VERSION ""

NS_ :

BS_:

BU_: bms bms_diag vcu charger motor dash

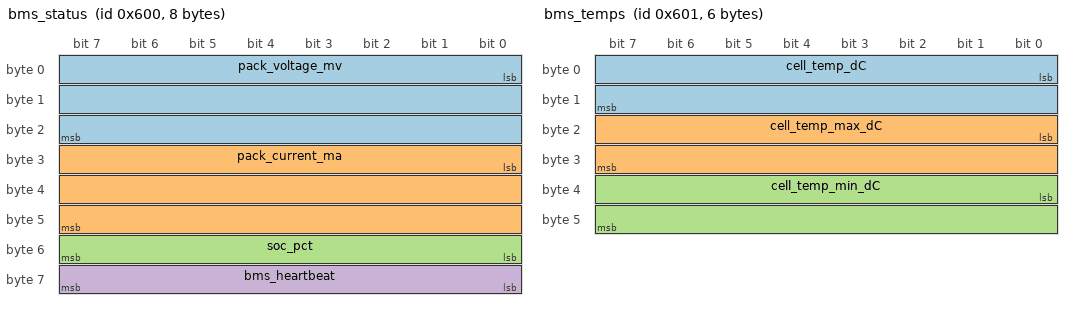
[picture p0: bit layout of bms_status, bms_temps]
BO_ 1536 bms_status: 8 bms
 SG_ pack_voltage_mv : 0|24@1+ (1,0) [0|16777215] "" Vector__XXX
 SG_ pack_current_ma : 24|24@1- (1,0) [-8388608|8388607] "" Vector__XXX
 SG_ soc_pct : 48|8@1+ (1,0) [0|255] "" Vector__XXX
 SG_ bms_heartbeat : 56|8@1+ (1,0) [0|255] "" Vector__XXX

BO_ 1537 bms_temps: 6 bms
 SG_ cell_temp_dC : 0|16@1- (1,0) [-32768|32767] "" Vector__XXX
 SG_ cell_temp_max_dC : 16|16@1- (1,0) [-32768|32767] "" Vector__XXX
 SG_ cell_temp_min_dC : 32|16@1- (1,0) [-32768|32767] "" Vector__XXX

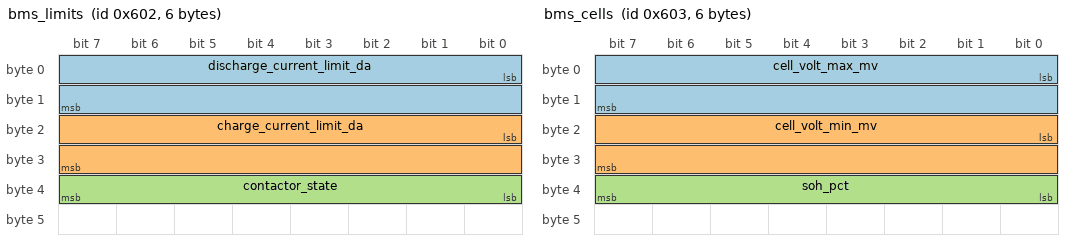
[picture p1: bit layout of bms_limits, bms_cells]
BO_ 1538 bms_limits: 6 bms
 SG_ discharge_current_limit_da : 0|16@1+ (1,0) [0|65535] "" Vector__XXX
 SG_ charge_current_limit_da : 16|16@1+ (1,0) [0|65535] "" Vector__XXX
 SG_ contactor_state : 32|8@1+ (1,0) [0|255] "" Vector__XXX

BO_ 1539 bms_cells: 6 bms
 SG_ cell_volt_max_mv : 0|16@1+ (1,0) [0|65535] "" Vector__XXX
 SG_ cell_volt_min_mv : 16|16@1+ (1,0) [0|65535] "" Vector__XXX
 SG_ soh_pct : 32|8@1+ (1,0) [0|255] "" Vector__XXX

BO_ 1540 bms_fault: 8 bms
 SG_ fault_code : 0|8@1+ (1,0) [0|255] "" Vector__XXX
 SG_ fault_counter : 8|8@1+ (1,0) [0|255] "" Vector__XXX

BO_ 1552 bms_diag_response: 8 bms_diag
 SG_ diag_response_code : 0|8@1+ (1,0) [0|255] "" Vector__XXX
 SG_ dtc_id : 16|16@1+ (1,0) [0|65535] "" Vector__XXX

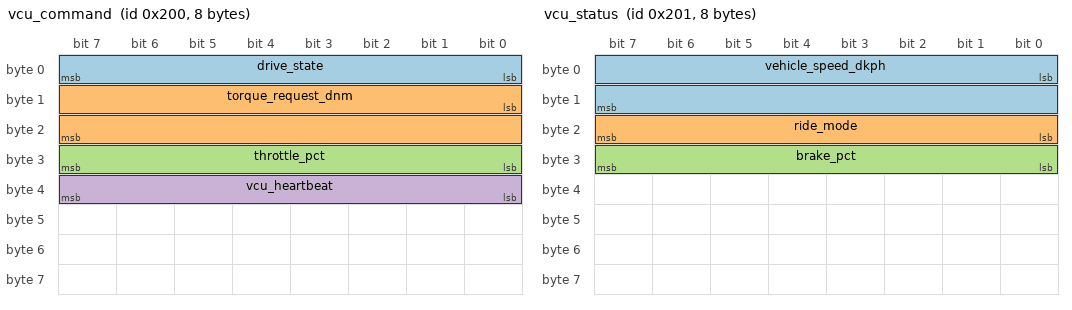
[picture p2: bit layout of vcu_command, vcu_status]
BO_ 512 vcu_command: 8 vcu
 SG_ drive_state : 0|8@1+ (1,0) [0|255] "" Vector__XXX
 SG_ torque_request_dnm : 8|16@1- (1,0) [-32768|32767] "" Vector__XXX
 SG_ throttle_pct : 24|8@1+ (1,0) [0|255] "" Vector__XXX
 SG_ vcu_heartbeat : 32|8@1+ (1,0) [0|255] "" Vector__XXX

BO_ 513 vcu_status: 8 vcu
 SG_ vehicle_speed_dkph : 0|16@1+ (1,0) [0|65535] "" Vector__XXX
 SG_ ride_mode : 16|8@1+ (1,0) [0|255] "" Vector__XXX
 SG_ brake_pct : 24|8@1+ (1,0) [0|255] "" Vector__XXX

BO_ 514 vcu_charge_control: 4 vcu
 SG_ charge_enable : 0|8@1+ (1,0) [0|255] "" Vector__XXX
 SG_ charge_current_request_da : 8|16@1+ (1,0) [0|65535] "" Vector__XXX

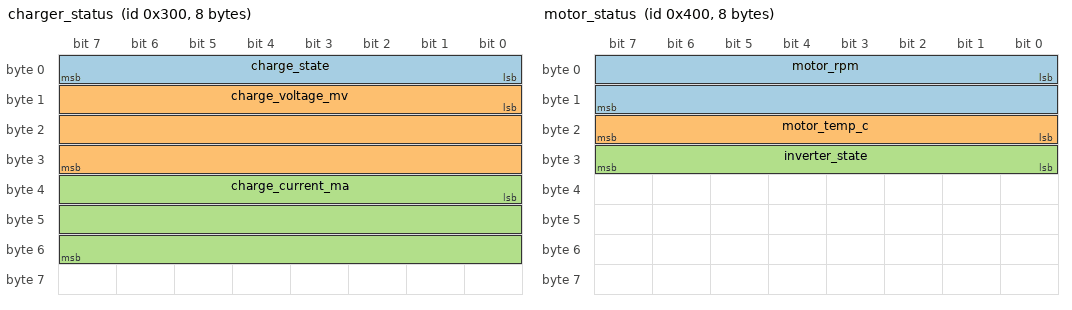
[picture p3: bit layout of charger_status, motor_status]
BO_ 768 charger_status: 8 charger
 SG_ charge_state : 0|8@1+ (1,0) [0|255] "" Vector__XXX
 SG_ charge_voltage_mv : 8|24@1+ (1,0) [0|16777215] "" Vector__XXX
 SG_ charge_current_ma : 32|24@1+ (1,0) [0|16777215] "" Vector__XXX

BO_ 769 charger_limits: 4 charger
 SG_ charge_plug_state : 0|8@1+ (1,0) [0|255] "" Vector__XXX
 SG_ max_charge_current_da : 8|16@1+ (1,0) [0|65535] "" Vector__XXX

BO_ 1024 motor_status: 8 motor
 SG_ motor_rpm : 0|16@1- (1,0) [-32768|32767] "" Vector__XXX
 SG_ motor_temp_c : 16|8@1- (1,0) [-128|127] "" Vector__XXX
 SG_ inverter_state : 24|8@1+ (1,0) [0|255] "" Vector__XXX

BO_ 1025 motor_power: 6 motor
 SG_ dc_bus_voltage_mv : 0|24@1+ (1,0) [0|16777215] "" Vector__XXX
 SG_ phase_current_ma : 24|24@1- (1,0) [-8388608|8388607] "" Vector__XXX

BO_ 1026 motor_wheel: 4 motor
 SG_ wheel_speed_rpm : 0|16@1+ (1,0) [0|65535] "" Vector__XXX
 SG_ regen_active : 16|8@1+ (1,0) [0|255] "" Vector__XXX

BO_ 1280 dash_telltales: 4 dash

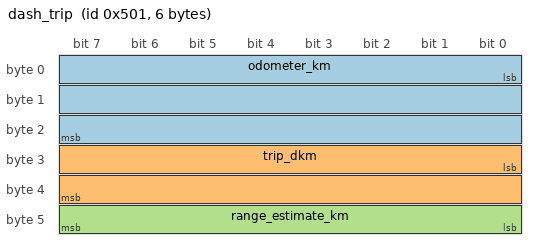
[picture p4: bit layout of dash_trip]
BO_ 1281 dash_trip: 6 dash
 SG_ odometer_km : 0|24@1+ (1,0) [0|16777215] "" Vector__XXX
 SG_ trip_dkm : 24|16@1+ (1,0) [0|65535] "" Vector__XXX
 SG_ range_estimate_km : 40|8@1+ (1,0) [0|255] "" Vector__XXX

CM_ "Generated by gen_dbc.py from catalog.yml. Do not edit by hand: edit the contract and regenerate, so this file and the test harness can never disagree. Byte-aligned subset; anything the subset cannot express is reported by the generator, never dropped silently.";

VAL_ 1540 fault_code 0 "NONE" 1 "OVERTEMP" 2 "OVERVOLT" 3 "UNDERVOLT" 4 "HEARTBEAT_LOST" 5 "CHARGE_LOST" 6 "OVERCURRENT" 7 "ISOLATION_FAULT" ;
VAL_ 1538 contactor_state 0 "OPEN" 1 "PRECHARGE" 2 "CLOSED" 3 "WELDED" 4 "FAULT" ;
VAL_ 512 drive_state 0 "PARKED" 1 "READY" 2 "DRIVE" 3 "REVERSE" 4 "LIMP" 5 "SHUTDOWN" ;
VAL_ 513 ride_mode 0 "ECO" 1 "CITY" 2 "SPORT" 3 "SERVICE" ;
VAL_ 768 charge_state 0 "IDLE" 1 "CONNECTED" 2 "HANDSHAKE" 3 "CONSTANT_CURRENT" 4 "CONSTANT_VOLTAGE" 5 "COMPLETE" 6 "SUSPENDED" 7 "FAULT" ;
VAL_ 769 charge_plug_state 0 "UNPLUGGED" 1 "PLUGGED_UNLOCKED" 2 "PLUGGED_LOCKED" 3 "PROXIMITY_FAULT" ;
VAL_ 1024 inverter_state 0 "OFF" 1 "STANDBY" 2 "RUN" 3 "REGEN" 4 "FAULT" ;
VAL_ 1552 diag_response_code 0 "NO_REQUEST" 1 "POSITIVE" 2 "PENDING" 3 "NEGATIVE_GENERAL" 4 "SESSION_REQUIRED" 5 "SECURITY_LOCKED" ;
